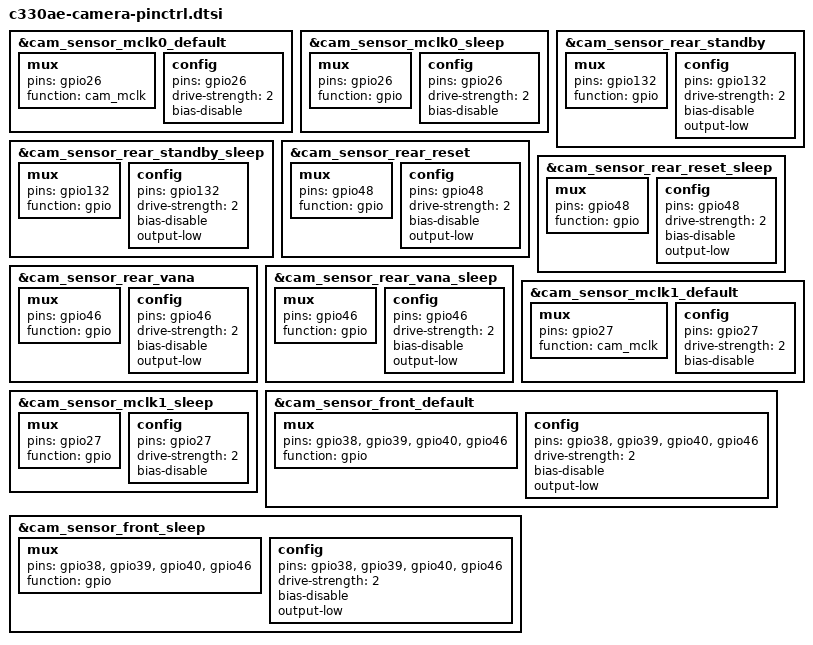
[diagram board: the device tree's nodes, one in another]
&cam_sensor_mclk0_default {
	mux {
		pins = "gpio26";
		function = "cam_mclk";
	};

	config {
		pins = "gpio26";
		drive-strength = <2>;
		bias-disable;
	};
};

&cam_sensor_mclk0_sleep {
	mux {
		pins = "gpio26";
		function = "gpio";
	};

	config {
		pins = "gpio26";
		drive-strength = <2>;
		bias-disable;
	};
};

&cam_sensor_rear_standby {
	mux {
		pins = "gpio132";
		function = "gpio";
	};

	config {
		pins = "gpio132";
		drive-strength = <2>;
		bias-disable;
		output-low;
	};
};

&cam_sensor_rear_standby_sleep {
	mux {
		pins = "gpio132";
		function = "gpio";
	};

	config {
		pins = "gpio132";
		drive-strength = <2>;
		bias-disable;
		output-low;
	};
};

&cam_sensor_rear_reset {
	mux {
		pins = "gpio48";
		function = "gpio";
	};

	config {
		pins = "gpio48";
		drive-strength = <2>;
		bias-disable;
		output-low;
	};
};

&cam_sensor_rear_reset_sleep {
	mux {
		pins = "gpio48";
		function = "gpio";
	};

	config {
		pins = "gpio48";
		drive-strength = <2>;
		bias-disable;
		output-low;
	};
};

&cam_sensor_rear_vana {
	mux {
		pins = "gpio46";
		function = "gpio";
	};

	config {
		pins = "gpio46";
		drive-strength = <2>;
		bias-disable;
		output-low;
	};
};

&cam_sensor_rear_vana_sleep {
	mux {
		pins = "gpio46";
		function = "gpio";
	};

	config {
		pins = "gpio46";
		drive-strength = <2>;
		bias-disable;
		output-low;
	};
};

&cam_sensor_mclk1_default {
	mux {
		pins = "gpio27";
		function = "cam_mclk";
	};

	config {
		pins = "gpio27";
		drive-strength = <2>;
		bias-disable;
	};
};

&cam_sensor_mclk1_sleep {
	mux {
		pins = "gpio27";
		function = "gpio";
	};

	config {
		pins = "gpio27";
		drive-strength = <2>;
		bias-disable;
	};
};

&cam_sensor_front_default {
	mux {
		pins = "gpio38", "gpio39", "gpio40", "gpio46";
		function = "gpio";
	};

	config {
		pins = "gpio38", "gpio39", "gpio40", "gpio46";
		drive-strength = <2>;
		bias-disable;
		output-low;
	};
};

&cam_sensor_front_sleep {
	mux {
		pins = "gpio38", "gpio39", "gpio40", "gpio46";
		function = "gpio";
	};

	config {
		pins = "gpio38", "gpio39", "gpio40", "gpio46";
		drive-strength = <2>;
		bias-disable;
		output-low;
	};
};
